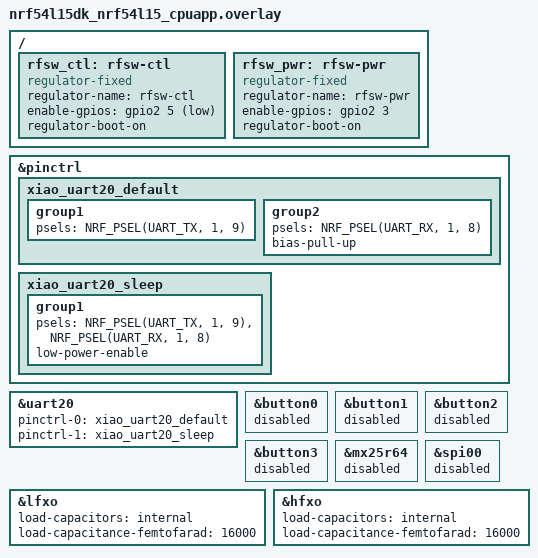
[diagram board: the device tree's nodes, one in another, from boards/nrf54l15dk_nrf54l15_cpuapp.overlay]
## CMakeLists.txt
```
# SPDX-License-Identifier: Apache-2.0
#
# Dedicated nRF54L15 LE Audio source fixture (RH1B): BAP
# unicast client that boots with persistent identity/bonds, accepts strict RH1A
# JSON via one quiet serial shell command, and runs a bounded
# connect/stream/teardown lifecycle with deterministic HIL1 records.
#
# Compiles the exact RH1A core modules (protocol, record, signal, state)
# plus the app coordinator, output queue/writer, TX send driver, and the
# real Bluetooth/BAP backend.  Production build has no test seam.

cmake_minimum_required(VERSION 3.20.0)
find_package(Zephyr REQUIRED HINTS $ENV{ZEPHYR_BASE})
project(hil_source_app)

if(NOT CONFIG_SOC_NRF54L15_CPUAPP)
  message(FATAL_ERROR "HIL source requires nRF54L15 CPUAPP")
endif()

target_sources(app PRIVATE
  src/main.c
  src/hil_source_app.c
  src/hil_source_controller_time_nrf54.c
  src/hil_source_output.c
  src/hil_source_tx.c
  src/hil_source_bap.c
  ${CMAKE_CURRENT_SOURCE_DIR}/../core/hil_source_protocol.c
  ${CMAKE_CURRENT_SOURCE_DIR}/../core/hil_source_record.c
  ${CMAKE_CURRENT_SOURCE_DIR}/../core/hil_source_signal.c
  ${CMAKE_CURRENT_SOURCE_DIR}/../core/hil_source_state.c
)

target_include_directories(app PRIVATE
  ${CMAKE_CURRENT_SOURCE_DIR}/src
  ${CMAKE_CURRENT_SOURCE_DIR}/../core
)

# LSP compile-database link: expose this app's compile_commands.json one
# directory up (hil/source/) so clangd's closest-ancestor discovery serves
# both this app tree and the ../core RH1A modules compiled into it.
# Idempotent; re-created on every reconfigure.
file(CREATE_LINK
     "${CMAKE_BINARY_DIR}/compile_commands.json"
     "${CMAKE_CURRENT_SOURCE_DIR}/../compile_commands.json"
     SYMBOLIC)
```

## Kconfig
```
# SPDX-License-Identifier: Apache-2.0
#
# Dedicated LE Audio source fixture application Kconfig.
#
# All run-time options are standard Zephyr/Bluetooth symbols set in
# prj.conf and the board conf. The RH1A core modules compile without any
# application-specific Kconfig; diagnostic fixture options live below.

source "Kconfig.zephyr"

config HIL_SOURCE_QOS_RTN
	int "HIL source CIS retransmission number (RTN)"
	default 5
	range 0 5
	help
	  RTN used in the source BAP QoS presets. Default 5 matches the
	  original frozen presets (nse=6). Diagnostic-only knob: the
	  receiver transport investigation varies it in fragments; normal
	  builds must not set it.

config HIL_SOURCE_QOS_PHY
	int "HIL source CIS PHY (1 or 2)"
	default 2
	range 1 2
	help
	  PHY used in the source BAP QoS presets. Default 2 (2M) matches the
	  original frozen presets. Diagnostic-only knob for the receiver
	  transport investigation; normal builds must not set it.

config HIL_SOURCE_TX_OUTSTANDING_TARGET
	int "HIL source TX outstanding target per stream"
	default 3
	range 1 6
	help
	  Per-stream in-flight SDU cap for the completion-paced TX loop.
	  Default 3 matches the original source-fixture backpressure design.
	  Diagnostic-only knob for the receiver transport investigation;
	  normal builds must not set it.
```

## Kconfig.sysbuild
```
# SPDX-License-Identifier: Apache-2.0
#
# Standalone nRF54L15 source builds with --no-sysbuild.

source "share/sysbuild/Kconfig"
```

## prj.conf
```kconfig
CONFIG_BT=y
CONFIG_BT_CENTRAL=y
CONFIG_BT_ISO_CENTRAL=y
CONFIG_BT_GATT_CLIENT=y
CONFIG_BT_GATT_AUTO_DISCOVER_CCC=y
CONFIG_BT_GATT_AUTO_UPDATE_MTU=y
CONFIG_BT_AUDIO=y
CONFIG_BT_BAP_UNICAST_CLIENT=y
CONFIG_BT_BAP_UNICAST_CLIENT_ASE_SNK_COUNT=2
CONFIG_BT_BAP_UNICAST_CLIENT_ASE_SRC_COUNT=0
CONFIG_BT_BAP_UNICAST_CLIENT_GROUP_STREAM_COUNT=2
CONFIG_BT_ISO_MAX_CHAN=2
CONFIG_BT_ISO_TX_MTU=255
CONFIG_BT_ISO_TX_BUF_COUNT=6
CONFIG_BT_SMP=y
CONFIG_BT_SMP_APP_PAIRING_ACCEPT=y
CONFIG_BT_SMP_ENFORCE_MITM=n
CONFIG_BT_KEYS_OVERWRITE_OLDEST=y
CONFIG_BT_SETTINGS=y
CONFIG_BT_PRIVACY=y
CONFIG_SETTINGS=y
CONFIG_FLASH=y
CONFIG_FLASH_MAP=y
CONFIG_FLASH_PAGE_LAYOUT=y
CONFIG_ZMS=y
CONFIG_SETTINGS_ZMS=y
CONFIG_BT_EXT_ADV=y
CONFIG_FPU=y
CONFIG_LIBLC3=y
CONFIG_SPEED_OPTIMIZATIONS=y
CONFIG_ASSERT=y
CONFIG_UTF8=y
CONFIG_NCS_BOOT_BANNER=n
CONFIG_BOOT_BANNER=n
CONFIG_SHELL=y
CONFIG_SHELL_BACKEND_SERIAL=y
# Keep HIL control shell above source worker/output threads during TX.
CONFIG_SHELL_THREAD_PRIORITY_OVERRIDE=y
CONFIG_SHELL_THREAD_PRIORITY=0
CONFIG_SHELL_CMD_BUFF_SIZE=512
CONFIG_SHELL_ARGC_MAX=3
CONFIG_SHELL_ECHO_STATUS=n
CONFIG_SHELL_VT100_COMMANDS=n
CONFIG_SHELL_METAKEYS=n
CONFIG_SHELL_TAB=n
CONFIG_SHELL_HISTORY=n
CONFIG_SHELL_WILDCARD=n
CONFIG_SHELL_MSG_CMD_NOT_FOUND=n
CONFIG_SHELL_HELP_ON_WRONG_ARGUMENT_COUNT=n
CONFIG_SHELL_PROMPT_CHANGE=n
CONFIG_SHELL_PROMPT_UART=""
CONFIG_SHELL_BACKEND_SERIAL_LOG_LEVEL_NONE=y
CONFIG_SHELL_TX_TIMEOUT_MS=0
CONFIG_SHELL_PRINTF_BUFF_SIZE=1024
CONFIG_SHELL_STACK_SIZE=8192
CONFIG_LOG=n
CONFIG_MAIN_STACK_SIZE=2048
CONFIG_SYSTEM_WORKQUEUE_STACK_SIZE=4096
CONFIG_BT_RX_STACK_SIZE=4096
CONFIG_HEAP_MEM_POOL_SIZE=4096
```

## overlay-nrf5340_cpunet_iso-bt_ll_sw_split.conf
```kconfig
# SPDX-License-Identifier: Apache-2.0
#
# Repository net-core overlay for the dedicated LE Audio source fixture.
# Applied on top of the hci_ipc sample base configuration
# (nrf5340_cpunet_iso_central-bt_ll_sw_split.conf) and may only tighten
# values: the fixture connects to exactly one receiver over two ISO
# streams with six controller TX buffers.

CONFIG_BT_MAX_CONN=1
CONFIG_BT_ISO_MAX_CHAN=2
CONFIG_BT_ISO_TX_BUF_COUNT=6
CONFIG_BT_CTLR_CONN_ISO_GROUPS=1
CONFIG_BT_CTLR_CONN_ISO_STREAMS=2
CONFIG_BT_CTLR_CONN_ISO_STREAMS_PER_GROUP=2
CONFIG_BT_CTLR_ISOAL_SOURCES=2
CONFIG_BT_CTLR_ISO_TX_BUFFERS=6
CONFIG_BT_CTLR_ISO_TX_BUFFER_SIZE=255
CONFIG_BT_CTLR_ISO_TX_SDU_LEN_MAX=247

# Dedicated lab source fixture. Use nRF5340's supported +3 dBm controller
# default so row commissioning does not depend on marginal 0 dBm RF links.
CONFIG_BT_CTLR_TX_PWR_PLUS_3=y

CONFIG_NCS_BOOT_BANNER=n
CONFIG_BOOT_BANNER=n
CONFIG_CONSOLE=n
CONFIG_UART_CONSOLE=n
CONFIG_STDOUT_CONSOLE=n
CONFIG_PRINTK=n
CONFIG_EARLY_CONSOLE=n
```

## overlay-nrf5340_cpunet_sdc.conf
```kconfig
# SPDX-License-Identifier: Apache-2.0
#
# Repository net-core overlay for the dedicated LE Audio source fixture:
# SoftDevice Controller (SDC) variant. Applied on top of the hci_ipc
# sample base prj.conf (controller-agnostic) instead of any SW-split
# sample configuration. The DT default on nrf5340_cpunet selects the
# SDC node (bt_hci_sdc okay, zephyr,bt-hci chosen), so no snippet and
# no DT overlay is needed; only this Kconfig overlay is applied.
#
# Decision record:
# docs/development/system-hil-rh3-modea10-sdc-handoff.md. The SW-split
# ISO-AL expires (SN_STRICT=y) or time-shifts (SN_STRICT=n) late TX SDUs
# under the completion-paced host at high CIG event duty; ModeA9 proved
# the mechanism and left the row failing frozen limits. SDC is the
# production-grade central ISO controller (BAP-tested per nrfxlib SDC
# isochronous_channels.rst; same shape as nrf5340_audio's SDC netcore +
# BAP unicast client host). Fixture connects to exactly one receiver
# over up to two connected ISO streams, central role only.

CONFIG_BT_BROADCASTER=n
CONFIG_BT_OBSERVER=y
CONFIG_BT_EXT_ADV=y
CONFIG_BT_PER_ADV=n
CONFIG_BT_PER_ADV_SYNC=n
CONFIG_BT_ISO_BROADCASTER=n
CONFIG_BT_ISO_SYNC_RECEIVER=n
CONFIG_BT_CENTRAL=y
CONFIG_BT_PERIPHERAL=n
CONFIG_BT_ISO_CENTRAL=y
CONFIG_BT_ISO_PERIPHERAL=n

# Host-side ISO channels for the raw-HCI IPC link. Keep the host ISO TX
# buffer count equal to the controller HCI TX buffer count (six) per the
# upstream sample's Newton's-cradle note.
CONFIG_BT_MAX_CONN=1
CONFIG_BT_ISO_MAX_CHAN=2
CONFIG_BT_ISO_TX_BUF_COUNT=6
CONFIG_BT_ISO_RX_BUF_COUNT=1

# Controller: SDC (default y on nrf5340 cpunet; DT default node),
# central ISO roles and buffers. One CIG, up to two CIS streams. The
# fixture is the audio source, so its ISO traffic is TX towards the
# receiver sink. Data-length and scan-data-length are SW-split-only
# symbols (BT_LL_SW_SPLIT dependency) and stay unset; SDC manages its
# own data length.
CONFIG_BT_LL_SOFTDEVICE=y
CONFIG_BT_CTLR_ASSERT_HANDLER=y

# Connected ISO: central role only. BT_CTLR_CONN_ISO is derived
# (default CENTRAL_ISO || PERIPHERAL_ISO) and not user-assignable;
# the central assignment below drives it. One CIG, up to two CIS
# streams.
CONFIG_BT_CTLR_CENTRAL_ISO=y
CONFIG_BT_CTLR_PERIPHERAL_ISO=n
CONFIG_BT_CTLR_CONN_ISO_GROUPS=1
CONFIG_BT_CTLR_CONN_ISO_STREAMS=2
CONFIG_BT_CTLR_CONN_ISO_STREAMS_PER_GROUP=2

# SDC ISO TX buffer pools. The HCI buffer count is shared across
# streams; its help text recommends larger values for short SDU
# intervals or quick successive sends. Six covers the completion-paced
# host bursts (outstanding target 3 per stream, two streams) and
# matches the app-core CONFIG_BT_ISO_TX_BUF_COUNT=6, keeping the three
# depths equal per the repo buffer-matching policy. PDU buffers per
# stream cover subevent pre-transmission and retransmission margin
# (SDC default 3 raised to the previous SW-split pool depth intent).
CONFIG_BT_CTLR_SDC_ISO_TX_HCI_BUFFER_COUNT=6
CONFIG_BT_CTLR_SDC_ISO_TX_PDU_BUFFER_PER_STREAM_COUNT=6

# SDC role counts: central-only fixture (zero peripheral roles).
CONFIG_BT_CTLR_SDC_PERIPHERAL_COUNT=0

# Clear application-core RTC0 when MPSL starts the controller RTC. The source
# scheduler uses this mirrored clock instead of deriving controller-now from an
# already-scheduled SDU timestamp.
CONFIG_MPSL_TRIGGER_IPC_TASK_ON_RTC_START=y
CONFIG_MPSL_TRIGGER_IPC_TASK_ON_RTC_START_CHANNEL=4

# TX power: +3 dBm, the nRF5340 maximum, keeps the fixture RF margin the
# SW-split build had (CONFIG_BT_CTLR_TX_PWR_PLUS_3). Under SDC the
# Zephyr TX_PWR choice is still consumed (nrf radio_nrf5_txp.h maps it
# to sdc_default_tx_power_set()), but its default is 0 dBm, so the
# assignment is required.
CONFIG_BT_CTLR_TX_PWR_PLUS_3=y

# Net core is silent; the app core owns the HIL1 console.
CONFIG_NCS_BOOT_BANNER=n
CONFIG_BOOT_BANNER=n
CONFIG_CONSOLE=n
CONFIG_UART_CONSOLE=n
CONFIG_STDOUT_CONSOLE=n
CONFIG_PRINTK=n
CONFIG_EARLY_CONSOLE=n
```

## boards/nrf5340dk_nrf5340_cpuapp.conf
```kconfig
# SPDX-License-Identifier: Apache-2.0
#
# nRF5340DK cpuapp board conf for the dedicated LE Audio source fixture.
# Mirrors the upstream bap_unicast_client nrf5340dk board conf: the HCI
# buffer sizes must cover the 255-byte ISO MTU and the extended events the
# host exchanges with the net-core controller (SDC via hci_ipc).

CONFIG_BT_BUF_EVT_RX_SIZE=255
CONFIG_BT_BUF_ACL_RX_SIZE=255
CONFIG_BT_BUF_ACL_TX_SIZE=251
CONFIG_BT_BUF_CMD_TX_SIZE=255

# Mirror the network-core controller RTC on application-core RTC0. Zephyr's
# system timer uses RTC1, leaving RTC0 for this synchronization route.
CONFIG_NRFX_RTC=y
CONFIG_NRFX_GPPI=y
```

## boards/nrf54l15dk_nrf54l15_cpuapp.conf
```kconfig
# SPDX-License-Identifier: Apache-2.0

# NCS 3.4.1: unused deprecated platform alias; SOC_SERIES_NRF54L remains enabled.
CONFIG_NRF_PLATFORM_LUMOS=n

CONFIG_REGULATOR=y
CONFIG_REGULATOR_FIXED_INIT_PRIORITY=45

CONFIG_BT_BUF_EVT_RX_SIZE=255
CONFIG_BT_BUF_ACL_RX_SIZE=255
CONFIG_BT_BUF_ACL_TX_SIZE=251
CONFIG_BT_BUF_CMD_TX_SIZE=255

# Bonded reconnect overflowed the 900-byte TX processor stack on the physical source.
# Budget this dedicated host/integrated-controller TX thread independently of RX.
CONFIG_BT_TX_PROCESSOR_STACK_SIZE=2048

CONFIG_BT_LL_SOFTDEVICE=y
CONFIG_BT_MAX_CONN=1
CONFIG_BT_CTLR_CENTRAL_ISO=y
CONFIG_BT_CTLR_PERIPHERAL_ISO=n
CONFIG_BT_CTLR_CONN_ISO_GROUPS=1
CONFIG_BT_CTLR_CONN_ISO_STREAMS=2
CONFIG_BT_CTLR_CONN_ISO_STREAMS_PER_GROUP=2
CONFIG_BT_CTLR_SDC_PERIPHERAL_COUNT=0
CONFIG_BT_CTLR_SDC_ISO_TX_HCI_BUFFER_COUNT=6
CONFIG_BT_CTLR_SDC_ISO_TX_PDU_BUFFER_PER_STREAM_COUNT=6
CONFIG_BT_CTLR_TX_PWR_PLUS_3=y
```

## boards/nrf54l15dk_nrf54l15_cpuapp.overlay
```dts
/*
 * Copyright (c) 2026
 * SPDX-License-Identifier: Apache-2.0
 *
 * XIAO nRF54L15 source-fixture overrides for the stock nrf54l15dk target.
 */

/ {
	rfsw_ctl: rfsw-ctl {
		compatible = "regulator-fixed";
		regulator-name = "rfsw-ctl";
		enable-gpios = <&gpio2 5 GPIO_ACTIVE_LOW>;
		regulator-boot-on;
	};

	rfsw_pwr: rfsw-pwr {
		compatible = "regulator-fixed";
		regulator-name = "rfsw-pwr";
		enable-gpios = <&gpio2 3 GPIO_ACTIVE_HIGH>;
		regulator-boot-on;
	};
};

&pinctrl {
	xiao_uart20_default: xiao_uart20_default {
		group1 {
			psels = <NRF_PSEL(UART_TX, 1, 9)>;
		};

		group2 {
			psels = <NRF_PSEL(UART_RX, 1, 8)>;
			bias-pull-up;
		};
	};

	xiao_uart20_sleep: xiao_uart20_sleep {
		group1 {
			psels = <NRF_PSEL(UART_TX, 1, 9)>,
				<NRF_PSEL(UART_RX, 1, 8)>;
			low-power-enable;
		};
	};
};

&uart20 {
	pinctrl-0 = <&xiao_uart20_default>;
	pinctrl-1 = <&xiao_uart20_sleep>;
	pinctrl-names = "default", "sleep";
};

&button0 {
	status = "disabled";
};

&button1 {
	status = "disabled";
};

&button2 {
	status = "disabled";
};

&button3 {
	status = "disabled";
};

&mx25r64 {
	status = "disabled";
};

&spi00 {
	status = "disabled";
};

&lfxo {
	load-capacitors = "internal";
	load-capacitance-femtofarad = <16000>;
	status = "okay";
};

&hfxo {
	load-capacitors = "internal";
	load-capacitance-femtofarad = <16000>;
	status = "okay";
};
```

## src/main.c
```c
/*
 * Copyright (c) 2026
 * SPDX-License-Identifier: Apache-2.0
 *
 * Dedicated LE Audio source fixture entry point.
 *
 * Initializes output and the nRF54L15 controller clock, then the Bluetooth/BAP
 * backend (bt_enable, settings_load, bt_is_ready, callbacks), then the app
 * coordinator (state and shell command), and returns into Zephyr threads.
 * A fatal init error emits one best-effort HIL1 status when possible and returns
 * nonzero; there is no restart loop.
 */

#include "hil_source_app.h"
#include "hil_source_bap.h"
#include "hil_source_controller_time.h"
#include "hil_source_output.h"

int main(void)
{
	int err;

	err = hil_source_output_init();
	if (err != 0) {
		/* No output available; nothing can be emitted. */
		return err;
	}

	err = hil_source_controller_time_init();
	if (err != 0) {
		hil_source_app_fatal_status("controller_time_init", err);
		return err;
	}

	err = hil_source_bap_init();
	if (err != 0) {
		hil_source_app_fatal_status("bap_init", err);
		return err;
	}

	err = hil_source_app_init();
	if (err != 0) {
		hil_source_app_fatal_status("app_init", err);
		return err;
	}

	return 0;
}
```

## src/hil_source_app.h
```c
/*
 * Copyright (c) 2026
 * SPDX-License-Identifier: Apache-2.0
 *
 * Dedicated LE Audio source fixture coordinator.
 *
 * The coordinator owns dispatch, the run worker, the TX stage
 * orchestration (pacing, lockstep, stage caps, outstanding, progress
 * timeout), the universal cleanup, and all HIL1 status/hello formatting.
 * All Bluetooth work happens through the backend ops table: in the
 * production build the table points at the real BAP/TX modules; under
 * CONFIG_HIL_SOURCE_APP_TEST the table is injected by the native test
 * suite so the coordinator runs against a scripted fake backend.
 */

#ifndef HIL_SOURCE_APP_H
#define HIL_SOURCE_APP_H

#include <stdbool.h>
#include <stddef.h>
#include <stdint.h>

#include <zephyr/bluetooth/addr.h>
#include <zephyr/kernel.h>

#include "hil_source_types.h"

#ifdef __cplusplus
extern "C" {
#endif

/* ── frozen timing / depth constants ──────────────────────────────── */

#define HIL_SOURCE_OP_TIMEOUT_CONNECT_MS    20000U
#define HIL_SOURCE_OP_TIMEOUT_SECURITY_MS   20000U
#define HIL_SOURCE_OP_TIMEOUT_DISCOVER_MS   10000U
#define HIL_SOURCE_OP_TIMEOUT_STREAM_MS     10000U
#define HIL_SOURCE_OUTPUT_SUBMIT_TIMEOUT_MS 1000U
#define HIL_SOURCE_IDLE_TERMINAL_WAIT_MS    15000U
#ifndef CONFIG_HIL_SOURCE_TX_OUTSTANDING_TARGET
#define HIL_SOURCE_TX_OUTSTANDING_TARGET 3U
#else
#define HIL_SOURCE_TX_OUTSTANDING_TARGET ((uint32_t)CONFIG_HIL_SOURCE_TX_OUTSTANDING_TARGET)
#endif
#define HIL_SOURCE_TX_PROGRESS_TIMEOUT_MS 2000U
#define HIL_SOURCE_TX_DRAIN_TIMEOUT_MS    5000U
#define HIL_SOURCE_MAX_STREAMS            2U

/* ── SDC timestamp-mode timing ─────────────────────────────────────── */

/* Encode first, then submit each pinned SDU against the direct nRF54L15
 * GRTC controller clock. The frozen 3000/2000 us margins retain headroom:
 * historically derived from SDC processing, the nRF53 reference scheduler's
 * IPC allowance, and worker/HCI jitter. Current XIAO uses no cross-core IPC. */
#define HIL_SOURCE_TX_TS_LEAD_TARGET_US 3000U
/* Pins closer than this to controller-now advance by whole intervals and
 * count as "pin_adv" evidence. */
#define HIL_SOURCE_TX_TS_MIN_AHEAD_US   2000U

/* Maximum encoded TX SDU byte size.  The ISO TX path is bounded by
 * CONFIG_BT_ISO_TX_MTU (255); the coordinator never uses the 1024-byte
 * output line scratch as SDU scratch. */
#define HIL_SOURCE_TX_SDU_MAX 255U

enum hil_source_stream_connect_outcome {
	HIL_SOURCE_STREAM_CONNECT_OUTCOME_CONNECTED,
	HIL_SOURCE_STREAM_CONNECT_OUTCOME_RETRYABLE_FAILURE,
	HIL_SOURCE_STREAM_CONNECT_OUTCOME_ERROR,
};

/* ── backend ops ──────────────────────────────────────────────────── */

struct hil_source_backend_ops {
	/* identity / bonds */
	int (*get_identity)(bt_addr_le_t *out);
	int (*bond_count)(void);
	int (*unpair)(const bt_addr_le_t *peer);
	/* True when the exact configured peer (address + type) has a stored
	 * bond.  Used to require an L2 bond before discovery on both fresh
	 * pairing and bonded reconnect. */
	bool (*peer_bonded)(const bt_addr_le_t *peer);

	/* run shape applied once per segment before connect */
	void (*set_run_shape)(enum hil_source_mode mode, enum hil_source_profile profile);

	/* run lifecycle: kick + completion sem */
	int (*kick_connect)(const bt_addr_le_t *addr);
	int (*kick_security)(void);
	int (*kick_discover)(void);
	int (*kick_configure)(uint8_t stream_count);
	int (*kick_qos)(uint8_t stream_count);
	/* Submit exactly one enable request for stream_idx.  The coordinator
	 * serializes multi-stream enable by waiting for sem_enabled and checking
	 * op_error before submitting the next stream. */
	int (*kick_enable)(uint8_t stream_idx);
	/* Submit one CIS connection request for stream_idx.  NCS permits only
	 * one pending bt_bap_stream_connect(); the coordinator waits for the
	 * matching public stream_ops.connected() completion before submitting the
	 * next request, and matching failed-CIS stream_ops.disconnected()
	 * completion is treated as a retryable failure, with at most one
	 * coordinator-worker retry for that same stream. */
	int (*kick_stream_connect)(uint8_t stream_idx);
	int (*kick_start)(uint8_t stream_count);

	/* Explicit TX activation: called once per segment after every
	 * sem_started completion and before the run advances to streaming.
	 * Production attaches the current segment's stream objects to the
	 * TX driver; the fake records the call. */
	int (*tx_start)(uint8_t stream_count);

	struct k_sem *(*sem_connected)(void);
	struct k_sem *(*sem_security)(void);
	struct k_sem *(*sem_discovered)(void);
	struct k_sem *(*sem_configured)(void);
	struct k_sem *(*sem_qos)(void);
	struct k_sem *(*sem_enabled)(void);
	struct k_sem *(*sem_stream_connected)(void);
	enum hil_source_stream_connect_outcome (*stream_connect_outcome)(uint8_t stream_idx);
	struct k_sem *(*sem_started)(void);

	/* most recent async lifecycle operation error (0 = none); the
	 * coordinator checks it after every bounded wait */
	int (*op_error)(void);

	/* TX send driver */
	int (*tx_send)(uint8_t stream_idx, uint16_t seq, const uint8_t *sdu, size_t len);
	/* Timestamp-pinned send (SDC timestamps mode): provide the SDU for the ISO
	 * event starting at `ts` (controller clock, us). A successful call does not
	 * prove peer receipt. A single untimestamped bootstrap SDU on stream 0
	 * establishes the CIG base; all regular segment SDUs use this API.
	 * Production backend must not wait for allocation, credits, or completion:
	 * coordinator holds app ownership and scheduling across a peer batch. */
	int (*tx_send_ts)(uint8_t stream_idx, uint16_t seq, const uint8_t *sdu, size_t len,
			  uint32_t ts);
	/* Read the controller-assigned event timestamp (us) for the previously
	 * provided SDU on a stream. Thread context only (synchronous HCI in
	 * production; scripted in the fake). */
	int (*tx_read_tx_ts)(uint8_t stream_idx, uint32_t *ts);
	/* Read controller time modulo 2^32 us. This must share the SDC clock
	 * domain; host uptime is not interchangeable with controller time.
	 * Must be a local nonblocking clock read, not a synchronous HCI command. */
	int (*tx_time_get)(uint32_t *time_us);
	/* Read HCI LE_Read_ISO_TX_Sync. Success requires a previously scheduled SDU,
	 * but repeated polls may return that same SDU. Historical "air" status
	 * counts therefore count successful polls, not aired SDUs. */
	int (*tx_read_sync)(uint8_t stream_idx, uint32_t *ts, uint32_t *seq);
	void (*tx_stop)(void);

	/* teardown */
	int (*kick_disable)(uint8_t stream_idx);
	struct k_sem *(*sem_disabled)(void);
	int (*kick_release)(uint8_t stream_idx);
	struct k_sem *(*sem_released)(void);
	int (*kick_disconnect)(void);
	struct k_sem *(*sem_disconnected)(void);
	bool (*conn_present)(void);
	bool (*stream_attached)(uint8_t stream_idx);
	int (*kick_group_delete)(void);
	void (*conn_unref)(void);
	void (*reset_segment)(void);

	/* status getters */
	uint8_t (*security_level)(void);
	int (*security_error)(void);
	uint8_t (*discovered_sink_count)(void);
	bool (*group_present)(void);
	uint8_t (*disconnect_reason)(void);
	uint8_t (*first_ascs_code)(void);
	uint8_t (*first_ascs_reason)(void);
};

/* ── public API ───────────────────────────────────────────────────── */

/* Initialize the coordinator: requires an active output (init order:
 * output first, then app), an injected/static backend, resets the run
 * state and configured IDs, and starts the worker thread.  Returns 0 or
 * a negative errno; a fatal init failure is not retried. */
int hil_source_app_init(void);

/* One best-effort HIL1 status record for a fatal boot failure
 * (kind status, command_id/run_id "boot", ok:false, error failed, with
 * the failing phase and errno in trusted data).  Never blocks the boot
 * path; a submit failure is swallowed. */
void hil_source_app_fatal_status(const char *phase, int err);

/* Dispatch one `hil <raw JSON>` command body (exactly the JSON object
 * span after the command name).  Returns 0 when the command was accepted
 * for handling or a negative errno for a rejected request. */
int hil_source_app_dispatch(const char *json, size_t len);

/* Sent-callback entry point, called by the real BAP stream ops in production
 * and by the fake backend in native tests. Decrements current-generation
 * outstanding and records callbacks while a run remains active. Callbacks
 * after teardown do not change logical outstanding. */
void hil_source_app_tx_sent(uint8_t stream_idx);

/* Format the full current status HIL1 line (envelope included) into buf.
 * Returns the written length or a negative errno; on failure the buffer
 * is an empty C string when cap is nonzero.  Exposed so tests can prove
 * formatter truncation fails closed. */
int hil_source_app_format_status_line(char *buf, size_t cap, const char *command_id,
				      const char *run_id);

#ifdef CONFIG_HIL_SOURCE_APP_TEST
/* Test seam: inject the backend ops table.  Must be called before
 * hil_source_app_init(). */
void hil_source_app_test_set_backend(const struct hil_source_backend_ops *ops);
#endif /* CONFIG_HIL_SOURCE_APP_TEST */

#ifdef __cplusplus
}
#endif

#endif /* HIL_SOURCE_APP_H */
```

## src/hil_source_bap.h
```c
/*
 * Copyright (c) 2026
 * SPDX-License-Identifier: Apache-2.0
 *
 * Real Bluetooth/BAP backend for the dedicated LE Audio source fixture
 * (RH1B).  Owns the connection, the BAP unicast client callbacks, the two
 * sink streams/endpoints, the unicast group, and the teardown primitives;
 * exposes them to the coordinator through the production backend ops
 * table.  Never drives lifecycle itself: the coordinator worker owns all
 * blocking operations.
 */

#ifndef HIL_SOURCE_BAP_H
#define HIL_SOURCE_BAP_H

#include "hil_source_app.h"

#ifdef __cplusplus
extern "C" {
#endif

/* Boot the Bluetooth/BAP backend: bt_enable(NULL), settings_load(),
 * require bt_is_ready(), register connection auth/auth-info callbacks,
 * GATT and BAP unicast client callbacks, register the stream ops, and
 * initialize the TX driver.  Returns 0 or a negative errno. */
int hil_source_bap_init(void);

/* The production backend ops table bound to the real BAP/TX modules. */
const struct hil_source_backend_ops *hil_source_bap_ops(void);

#ifdef __cplusplus
}
#endif

#endif /* HIL_SOURCE_BAP_H */
```

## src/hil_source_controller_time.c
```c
/*
 * Copyright (c) 2026
 * SPDX-License-Identifier: Apache-2.0
 *
 * Mirror the nRF5340 network-core controller RTC on application-core RTC0.
 * MPSL publishes its RTC-start event over IPC channel 4; PPI clears RTC0 on
 * that event. Only current controller time is needed here, so no high-frequency
 * TIMER or hardware presentation trigger is configured.
 */

#include <errno.h>
#include <stdbool.h>
#include <stdint.h>

#include <hal/nrf_ipc.h>
#include <helpers/nrfx_gppi.h>
#include <nrfx_rtc.h>
#include <zephyr/device.h>
#include <zephyr/drivers/mbox.h>
#include <zephyr/init.h>
#include <zephyr/irq.h>
#include <zephyr/kernel.h>

#include "hil_source_controller_time.h"

#define HIL_SOURCE_CONTROLLER_IPC_CHANNEL      4U
#define HIL_SOURCE_CONTROLLER_RTC_COUNTER_BITS 24U

static nrfx_rtc_t controller_rtc = NRFX_RTC_INSTANCE(NRF_RTC0);
static nrfx_gppi_handle_t rtc_start_connection;
static volatile uint32_t rtc_overflows;
static volatile bool controller_time_synchronized;
static volatile bool controller_time_fault;
static volatile bool controller_start_seen;
static bool controller_time_initialized;

static void controller_start_handler(const struct device *dev, mbox_channel_id_t channel_id,
				     void *user_data, struct mbox_msg *data)
{
	ARG_UNUSED(dev);
	ARG_UNUSED(channel_id);
	ARG_UNUSED(user_data);
	ARG_UNUSED(data);

	/* One APP boot supports one controller clock epoch. A second pulse means
	 * CPUNET restarted while APP remained alive. PPI already cleared RTC0, so
	 * fail closed instead of combining epochs. */
	if (controller_start_seen) {
		controller_time_synchronized = false;
		controller_time_fault = true;
		return;
	}
	nrf_rtc_event_clear(controller_rtc.p_reg, NRF_RTC_EVENT_OVERFLOW);
	rtc_overflows = 0U;
	controller_start_seen = true;
	controller_time_synchronized = true;
}

static void controller_rtc_handler(nrf_rtc_event_t event_type, void *context)
{
	ARG_UNUSED(context);

	if (event_type == NRF_RTC_EVENT_OVERFLOW && controller_time_synchronized &&
	    !controller_time_fault) {
		rtc_overflows++;
	}
}

int hil_source_controller_time_init(void)
{
	const nrfx_rtc_config_t config = NRFX_RTC_DEFAULT_CONFIG;
	const struct device *mbox = DEVICE_DT_GET(DT_NODELABEL(mbox));
	uint32_t event_endpoint;
	uint32_t task_endpoint;
	int ret;

	if (controller_time_initialized) {
		return 0;
	}
	if (!device_is_ready(mbox)) {
		return -ENODEV;
	}
	controller_time_synchronized = false;
	controller_time_fault = false;
	controller_start_seen = false;
	rtc_overflows = 0U;

	ret = nrfx_rtc_init(&controller_rtc, &config, controller_rtc_handler);
	if (ret != 0) {
		return ret;
	}

	IRQ_CONNECT(NRFX_IRQ_NUMBER_GET(NRF_RTC_INST_GET(0)), IRQ_PRIO_LOWEST, nrfx_rtc_irq_handler,
		    &controller_rtc, 0);
	nrfx_rtc_overflow_enable(&controller_rtc, true);
	nrfx_rtc_counter_clear(&controller_rtc);

	ret = mbox_register_callback(mbox, HIL_SOURCE_CONTROLLER_IPC_CHANNEL,
				     controller_start_handler, NULL);
	if (ret != 0) {
		goto fail_rtc;
	}

	/* Mbox driver maps receive event 4 to channel 4. Arm its event-to-RTC0
	 * route before Bluetooth can start CPUNET. */
	nrf_ipc_event_clear(NRF_IPC, NRF_IPC_EVENT_RECEIVE_4);
	event_endpoint = nrf_ipc_event_address_get(NRF_IPC, NRF_IPC_EVENT_RECEIVE_4);
	task_endpoint = nrfx_rtc_task_address_get(&controller_rtc, NRF_RTC_TASK_CLEAR);
	ret = nrfx_gppi_conn_alloc(event_endpoint, task_endpoint, &rtc_start_connection);
	if (ret < 0) {
		goto fail_callback;
	}
	nrfx_gppi_conn_enable(rtc_start_connection);

	ret = mbox_set_enabled(mbox, HIL_SOURCE_CONTROLLER_IPC_CHANNEL, true);
	if (ret != 0) {
		goto fail_connection;
	}
	nrfx_rtc_enable(&controller_rtc);

	controller_time_initialized = true;
	return 0;

fail_connection:
	nrfx_gppi_conn_disable(rtc_start_connection);
	nrfx_gppi_conn_free(event_endpoint, task_endpoint, rtc_start_connection);
fail_callback:
	(void)mbox_register_callback(mbox, HIL_SOURCE_CONTROLLER_IPC_CHANNEL, NULL, NULL);
fail_rtc:
	nrfx_rtc_uninit(&controller_rtc);
	return ret;
}

int hil_source_controller_time_get(uint32_t *time_us)
{
	uint64_t ticks;
	uint32_t overflows;
	uint32_t counter;
	unsigned int key;

	if (time_us == NULL) {
		return -EINVAL;
	}
	/* Keep overflow accounting coherent if wrap occurs while IRQ delivery is
	 * masked. One RTC tick is 1 / 32768 s; 15625 / 512 is the exact
	 * microsecond conversion ratio. */
	key = irq_lock();
	if (controller_time_fault) {
		irq_unlock(key);
		return -EIO;
	}
	if (!controller_time_synchronized ||
	    nrf_ipc_event_check(NRF_IPC, NRF_IPC_EVENT_RECEIVE_4)) {
		irq_unlock(key);
		return -EAGAIN;
	}
	overflows = rtc_overflows;
	counter = nrf_rtc_counter_get(controller_rtc.p_reg);
	if (nrf_rtc_event_check(controller_rtc.p_reg, NRF_RTC_EVENT_OVERFLOW)) {
		counter = nrf_rtc_counter_get(controller_rtc.p_reg);
		overflows++;
	}
	if (nrf_ipc_event_check(NRF_IPC, NRF_IPC_EVENT_RECEIVE_4)) {
		irq_unlock(key);
		return -EAGAIN;
	}
	irq_unlock(key);

	ticks = ((uint64_t)overflows << HIL_SOURCE_CONTROLLER_RTC_COUNTER_BITS) + counter;
	*time_us = (uint32_t)((ticks * 15625ULL) / 512ULL);
	return 0;
}

static int hil_source_controller_time_sys_init(void)
{
	return hil_source_controller_time_init();
}

/* Arm as early as Nordic's reference implementation. main() calls the same
 * idempotent initializer and checks its result, so init failure is observable. */
SYS_INIT(hil_source_controller_time_sys_init, POST_KERNEL, CONFIG_KERNEL_INIT_PRIORITY_DEFAULT);
```

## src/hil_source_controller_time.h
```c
/*
 * Copyright (c) 2026
 * SPDX-License-Identifier: Apache-2.0
 *
 * Platform view of the SoftDevice Controller clock.
 */

#ifndef HIL_SOURCE_CONTROLLER_TIME_H
#define HIL_SOURCE_CONTROLLER_TIME_H

#include <stdint.h>

#ifdef __cplusplus
extern "C" {
#endif

/* Initialize platform controller-clock infrastructure. */
int hil_source_controller_time_init(void);

/* Read nRF54L15 controller time from Zephyr-owned GRTC, modulo 2^32 us.
 * NULL returns -EINVAL; uninitialized GRTC returns -ENODEV; not-ready
 * GRTC returns -EAGAIN. On success, writes *time_us and returns 0.
 * No network-core mirror or mirrored clock epoch is used. */
int hil_source_controller_time_get(uint32_t *time_us);

#ifdef __cplusplus
}
#endif

#endif /* HIL_SOURCE_CONTROLLER_TIME_H */
```

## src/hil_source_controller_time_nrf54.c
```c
/*
 * Copyright (c) 2026
 * SPDX-License-Identifier: Apache-2.0
 *
 * Read the nRF54L15 SoftDevice Controller clock from Zephyr-owned GRTC.
 */

#include <errno.h>
#include <stdint.h>

#include <nrfx_grtc.h>

#include "hil_source_controller_time.h"

int hil_source_controller_time_init(void)
{
	return nrfx_grtc_init_check() ? 0 : -ENODEV;
}

int hil_source_controller_time_get(uint32_t *time_us)
{
	if (time_us == NULL) {
		return -EINVAL;
	}
	if (!nrfx_grtc_init_check()) {
		return -ENODEV;
	}
	if (!nrfx_grtc_ready_check()) {
		return -EAGAIN;
	}

	*time_us = (uint32_t)nrfx_grtc_syscounter_get();
	return 0;
}
```

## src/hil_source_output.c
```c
/*
 * Copyright (c) 2026
 * SPDX-License-Identifier: Apache-2.0
 *
 * HIL1 output queue and single writer (RH1B).
 *
 * One queue (eight lines of 1024 bytes plus length) and one writer thread.
 * Validation happens before enqueue: a rejected line is never truncated
 * and never partially emitted.  A queue timeout on submit is a fatal
 * runtime error the caller (coordinator) turns into an abort.  Under
 * CONFIG_HIL_SOURCE_APP_TEST the writer thread is replaced by a
 * test-owned drain so native tests capture exact submitted lines without
 * a shell.
 */

#include <errno.h>
#include <string.h>

#include <zephyr/kernel.h>
#include <zephyr/shell/shell.h>
#include <zephyr/shell/shell_uart.h>
#include <zephyr/sys/util.h>

#include "hil_source_output.h"

struct hil_source_output_line {
	char data[HIL_SOURCE_OUTPUT_LINE_SIZE];
	uint16_t len;
};

K_MSGQ_DEFINE(output_queue, sizeof(struct hil_source_output_line), HIL_SOURCE_OUTPUT_QUEUE_DEPTH,
	      4);
static bool output_active;

#if !defined(CONFIG_HIL_SOURCE_APP_TEST)
/* Each dequeue owns one 1026-byte output line on stack before shell_fprintf()
 * adds its call depth. Keep enough bounded headroom for both operations. */
K_THREAD_STACK_DEFINE(output_writer_stack, 4096);
static struct k_thread output_writer_thread;

static void output_writer_fn(void *a, void *b, void *c)
{
	const struct shell *sh = shell_backend_uart_get_ptr();
	struct hil_source_output_line line;

	ARG_UNUSED(a);
	ARG_UNUSED(b);
	ARG_UNUSED(c);

	while (true) {
		if (k_msgq_get(&output_queue, &line, K_FOREVER) != 0) {
			continue;
		}
		if (sh != NULL) {
			shell_fprintf(sh, SHELL_NORMAL, "%.*s\n", (int)line.len, line.data);
		}
	}
}
#endif /* !CONFIG_HIL_SOURCE_APP_TEST */

#ifdef CONFIG_HIL_SOURCE_APP_TEST
static void (*capture_fn)(const char *line, size_t len, void *arg);
static void *capture_arg;
#endif

int hil_source_output_init(void)
{
	if (output_active) {
		return 0; /* idempotent */
	}
#if !defined(CONFIG_HIL_SOURCE_APP_TEST)
	/* Production output requires a live serial shell backend before the
	 * writer may start; without it every line would be silently dropped.
	 * The test build stays capture-backed and never requires the shell. */
	if (shell_backend_uart_get_ptr() == NULL) {
		return -ENODEV;
	}
#endif /* !CONFIG_HIL_SOURCE_APP_TEST */
	k_msgq_purge(&output_queue);
	output_active = true;

#if !defined(CONFIG_HIL_SOURCE_APP_TEST)
	k_thread_create(&output_writer_thread, output_writer_stack,
			K_KERNEL_STACK_SIZEOF(output_writer_stack), output_writer_fn, NULL, NULL,
			NULL, K_PRIO_PREEMPT(6), 0, K_NO_WAIT);
	k_thread_name_set(&output_writer_thread, "hil_output");
#endif /* !CONFIG_HIL_SOURCE_APP_TEST */

	return 0;
}

bool hil_source_output_active(void)
{
	return output_active;
}

int hil_source_output_submit(const char *line, size_t len, uint32_t timeout_ms)
{
	struct hil_source_output_line entry;
	k_timeout_t timeout;
	size_t i;

	if (!output_active || line == NULL) {
		return -ENODEV;
	}
	if (len > HIL_SOURCE_OUTPUT_LINE_SIZE) {
		return -EOVERFLOW;
	}
	/* Only HIL1-prefixed records may leave the fixture; everything else
	 * is rejected up front. */
	if (len < 5U || memcmp(line, "HIL1 ", 5U) != 0) {
		return -EINVAL;
	}
	for (i = 0U; i < len; i++) {
		char c = line[i];

		if (c == '\r' || c == '\n' || c == '\0') {
			return -EINVAL;
		}
	}
	if (len == 0U) {
		return -EINVAL;
	}

	entry.len = (uint16_t)len;
	memcpy(entry.data, line, len);

	timeout = (timeout_ms == 0U) ? K_NO_WAIT : K_MSEC(timeout_ms);
	if (k_msgq_put(&output_queue, &entry, timeout) != 0) {
		return -EAGAIN;
	}
	return 0;
}

#ifdef CONFIG_HIL_SOURCE_APP_TEST
void hil_source_output_test_set_capture(void (*fn)(const char *line, size_t len, void *arg),
					void *arg)
{
	capture_fn = fn;
	capture_arg = arg;
}

uint32_t hil_source_output_test_drain(void)
{
	struct hil_source_output_line entry;
	uint32_t drained = 0U;

	while (k_msgq_get(&output_queue, &entry, K_NO_WAIT) == 0) {
		if (capture_fn != NULL) {
			capture_fn(entry.data, entry.len, capture_arg);
		}
		drained++;
	}
	return drained;
}
#endif /* CONFIG_HIL_SOURCE_APP_TEST */
```

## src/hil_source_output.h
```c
/*
 * Copyright (c) 2026
 * SPDX-License-Identifier: Apache-2.0
 *
 * HIL1 output queue and single writer (RH1B).
 *
 * Every HIL1 line, command response, and async event leaves the fixture
 * through this one module: one queue and one writer thread.  No direct
 * printk/printf/shell_print/shell_fprintf outside hil_source_output.c.
 */

#ifndef HIL_SOURCE_OUTPUT_H
#define HIL_SOURCE_OUTPUT_H

#include <stdbool.h>
#include <stddef.h>
#include <stdint.h>

#ifdef __cplusplus
extern "C" {
#endif

/* Queue holds eight complete lines of 1024 bytes plus length. 1024 bytes
 * fits the maximum legal command/run IDs (63/64) in a two-stream status
 * record; the TX SDU path is separately bounded by HIL_SOURCE_TX_SDU_MAX
 * and never uses this scratch. */
#define HIL_SOURCE_OUTPUT_LINE_SIZE   1024U
#define HIL_SOURCE_OUTPUT_QUEUE_DEPTH 8U

/* Initialize the output queue and start the writer thread (production
 * build).  Under CONFIG_HIL_SOURCE_APP_TEST no thread is started; the
 * test drains the queue through hil_source_output_test_drain().  Returns
 * 0 or a negative errno. */
int hil_source_output_init(void);

/* True once init succeeded and before any shutdown; inactive output
 * rejects submissions. */
bool hil_source_output_active(void);

/* Submit one complete line (no line terminator).  Rejects a non-HIL1
 * prefix, an embedded CR/LF/NUL, an overlong line, or an inactive output;
 * never truncates.  `timeout_ms` bounds the queue wait (the worker and
 * dispatch paths use 1000 ms; a queue timeout is a fatal runtime error
 * and triggers an abort where a run exists).  Returns 0 or a negative
 * errno. */
int hil_source_output_submit(const char *line, size_t len, uint32_t timeout_ms);

#ifdef CONFIG_HIL_SOURCE_APP_TEST
/* Test seam: set the capture callback invoked for every drained line.
 * Passing a NULL fn disables capture (lines are still drained). */
void hil_source_output_test_set_capture(void (*fn)(const char *line, size_t len, void *arg),
					void *arg);

/* Drain every queued line through the capture callback and return the
 * number of drained lines. */
uint32_t hil_source_output_test_drain(void);
#endif /* CONFIG_HIL_SOURCE_APP_TEST */

#ifdef __cplusplus
}
#endif

#endif /* HIL_SOURCE_OUTPUT_H */
```

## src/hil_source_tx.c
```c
/*
 * Copyright (c) 2026
 * SPDX-License-Identifier: Apache-2.0
 *
 * TX send driver: fixed net_buf pool + bt_bap_stream_send(), plus
 * SDC timestamp-mode support: bt_bap_stream_send_ts() and the HCI VS ISO
 * Read TX Timestamp readback used to establish the CIG event grid
 * (nrfxlib SDC isochronous_channels.rst "preferred way of providing data").
 */

#include <errno.h>
#include <string.h>

#include <zephyr/bluetooth/audio/bap.h>
#include <zephyr/bluetooth/hci.h>
#include <zephyr/bluetooth/iso.h>
#include <zephyr/kernel.h>
#include <zephyr/net_buf.h>

#include <bluetooth/hci_vs_sdc.h>

#include "hil_source_tx.h"

#define HIL_SOURCE_TX_POOL_COUNT          CONFIG_BT_ISO_TX_BUF_COUNT
#define HIL_SOURCE_TX_MTU                 CONFIG_BT_ISO_TX_MTU
#define HIL_SOURCE_TX_CONN_HANDLE_INVALID UINT16_MAX

static struct bt_bap_stream *tx_streams[HIL_SOURCE_MAX_TX_STREAMS];
static uint8_t tx_stream_count;
static bool tx_stopped;
/* Cached ISO connection handles per stream. HCI handle zero is valid, so
 * UINT16_MAX marks an unresolved handle. */
static uint16_t tx_conn_handles[HIL_SOURCE_MAX_TX_STREAMS];

NET_BUF_POOL_FIXED_DEFINE(tx_pool, HIL_SOURCE_TX_POOL_COUNT, BT_ISO_SDU_BUF_SIZE(HIL_SOURCE_TX_MTU),
			  CONFIG_BT_CONN_TX_USER_DATA_SIZE, NULL);

int hil_source_tx_init(void)
{
	tx_stopped = false;
	return 0;
}

int hil_source_tx_attach(struct bt_bap_stream *streams, uint8_t count)
{
	uint8_t i;

	if (streams == NULL || count == 0U || count > HIL_SOURCE_MAX_TX_STREAMS) {
		return -EINVAL;
	}
	for (i = 0U; i < count; i++) {
		tx_streams[i] = &streams[i];
		tx_conn_handles[i] = HIL_SOURCE_TX_CONN_HANDLE_INVALID;
	}
	tx_stream_count = count;
	tx_stopped = false;
	return 0;
}

int hil_source_tx_send(uint8_t stream_idx, uint16_t seq, const uint8_t *sdu, size_t len)
{
	struct bt_bap_stream *stream;
	struct net_buf *buf;
	int err;

	if (tx_stopped) {
		return -EIO;
	}
	if (stream_idx >= tx_stream_count || sdu == NULL || len == 0U) {
		return -EINVAL;
	}
	if (len > HIL_SOURCE_TX_MTU) {
		return -EOVERFLOW;
	}
	stream = tx_streams[stream_idx];

	buf = net_buf_alloc(&tx_pool, K_NO_WAIT);
	if (buf == NULL) {
		return -ENOBUFS;
	}
	net_buf_reserve(buf, BT_ISO_CHAN_SEND_RESERVE);
	net_buf_add_mem(buf, sdu, len);

	err = bt_bap_stream_send(stream, buf, seq);
	if (err != 0) {
		net_buf_unref(buf);
		return err;
	}
	return 0;
}

int hil_source_tx_send_ts(uint8_t stream_idx, uint16_t seq, const uint8_t *sdu, size_t len,
			  uint32_t ts)
{
	struct bt_bap_stream *stream;
	struct net_buf *buf;
	int err;

	if (tx_stopped) {
		return -EIO;
	}
	if (stream_idx >= tx_stream_count || sdu == NULL || len == 0U) {
		return -EINVAL;
	}
	if (len > HIL_SOURCE_TX_MTU) {
		return -EOVERFLOW;
	}
	stream = tx_streams[stream_idx];

	buf = net_buf_alloc(&tx_pool, K_NO_WAIT);
	if (buf == NULL) {
		return -ENOBUFS;
	}
	net_buf_reserve(buf, BT_ISO_CHAN_SEND_RESERVE);
	net_buf_add_mem(buf, sdu, len);

	err = bt_bap_stream_send_ts(stream, buf, seq, ts);
	if (err != 0) {
		net_buf_unref(buf);
		return err;
	}
	return 0;
}

int hil_source_tx_read_sync(uint8_t stream_idx, uint32_t *ts, uint32_t *seq)
{
	struct bt_bap_stream *stream;
	struct bt_iso_tx_info info;
	int err;

	if (ts == NULL || seq == NULL) {
		return -EINVAL;
	}
	if (tx_stopped || stream_idx >= tx_stream_count) {
		return -EIO;
	}
	stream = tx_streams[stream_idx];

	err = bt_bap_stream_get_tx_sync(stream, &info);
	if (err != 0) {
		return err;
	}
	*ts = info.ts;
	*seq = info.seq_num;
	return 0;
}

int hil_source_tx_read_tx_ts(uint8_t stream_idx, uint32_t *ts)
{
	struct bt_bap_stream *stream;
	sdc_hci_cmd_vs_iso_read_tx_timestamp_t params;
	sdc_hci_cmd_vs_iso_read_tx_timestamp_return_t rsp;
	uint16_t conn_handle;
	int err;

	if (ts == NULL) {
		return -EINVAL;
	}
	if (tx_stopped || stream_idx >= tx_stream_count) {
		return -EIO;
	}
	stream = tx_streams[stream_idx];

	conn_handle = tx_conn_handles[stream_idx];
	if (conn_handle == HIL_SOURCE_TX_CONN_HANDLE_INVALID) {
		const struct bt_conn *iso_conn;

		/* bt_bap_stream.iso is the public ISO channel reference,
		 * valid once the stream is in a group (bap.h). */
		if (stream->iso == NULL || stream->iso->iso == NULL) {
			return -ENOTCONN;
		}
		iso_conn = stream->iso->iso;
		err = bt_hci_get_conn_handle(iso_conn, &conn_handle);
		if (err != 0) {
			return err;
		}
		tx_conn_handles[stream_idx] = conn_handle;
	}

	params.conn_handle = conn_handle;
	err = hci_vs_sdc_iso_read_tx_timestamp(&params, &rsp);
	if (err != 0) {
		return err;
	}
	*ts = rsp.tx_time_stamp;
	return 0;
}

void hil_source_tx_stop(void)
{
	uint8_t i;

	tx_stopped = true;
	/* Reject further sends and clear the attached stream pointers and
	 * count: the next tx_start re-activates only the exact current
	 * segment stream count. */
	for (i = 0U; i < HIL_SOURCE_MAX_TX_STREAMS; i++) {
		tx_streams[i] = NULL;
		tx_conn_handles[i] = HIL_SOURCE_TX_CONN_HANDLE_INVALID;
	}
	tx_stream_count = 0U;
}
```

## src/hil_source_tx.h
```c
/*
 * Copyright (c) 2026
 * SPDX-License-Identifier: Apache-2.0
 *
 * TX send driver for the dedicated LE Audio source fixture.
 *
 * Production TX path: a fixed net_buf pool sized for the
 * 255-byte ISO MTU, reserve of BT_ISO_CHAN_SEND_RESERVE, and the actual
 * bt_bap_stream_send() calls. The coordinator owns frame pacing,
 * lockstep, stage caps, sequence/outstanding bookkeeping, and submitted
 * counters; this module only moves encoded SDUs onto a stream.
 *
 * SDC timestamp mode: hil_source_tx_send_ts() provides one SDU for a
 * controller-clock ISO event via bt_bap_stream_send_ts().
 * hil_source_tx_read_tx_ts() reads the event timestamp assigned to the
 * previously provided SDU through the SDC HCI VS command. Nordic SDK
 * iso_time_sync and nrf5340_audio are external reference patterns, not
 * required board targets. One untimestamped bootstrap SDU
 * on stream 0 establishes the shared CIG event grid. All regular segment SDUs
 * then use the learned grid.
 */

#ifndef HIL_SOURCE_TX_H
#define HIL_SOURCE_TX_H

#include <stddef.h>
#include <stdint.h>

#include <zephyr/bluetooth/audio/bap.h>

/* Maximum number of concurrent TX streams (two for Mode A). */
#define HIL_SOURCE_MAX_TX_STREAMS 2U

#ifdef __cplusplus
extern "C" {
#endif

/* Initialize the fixed TX net_buf pool.  Returns 0 or a negative errno. */
int hil_source_tx_init(void);

/* Attach the production stream objects (one per configured stream).
 * Called once per segment before the first send. */
int hil_source_tx_attach(struct bt_bap_stream *streams, uint8_t count);

/* Send one encoded SDU on a stream with the given sequence number.
 * Allocates from the fixed pool, copies the SDU, and hands the buffer to
 * the ISO stack.  Returns 0 on success (buffer ownership transferred) or
 * a negative errno (buffer unref'd by the driver).  Sends after
 * hil_source_tx_stop() are rejected. */
int hil_source_tx_send(uint8_t stream_idx, uint16_t seq, const uint8_t *sdu, size_t len);

/* Timestamp-pinned send (SDC timestamps mode): provide this SDU for the ISO
 * event whose CIG-event start is `ts` (controller clock, microseconds). Same
 * buffer semantics as hil_source_tx_send(). Successful submission does not
 * prove peer receipt. The coordinator only supplies future timestamps because
 * SDC flushes an SDU whose timestamp is already past when processed. */
int hil_source_tx_send_ts(uint8_t stream_idx, uint16_t seq, const uint8_t *sdu, size_t len,
			  uint32_t ts);

/* Read the controller-assigned TX timestamp (CIG event start, controller-clock
 * microseconds) for the previously provided SDU on a stream. Thread context
 * only (synchronous HCI). Returns 0 and sets *ts, or a negative errno, for
 * example -ENOTCONN before a stream has an ISO connection or during teardown. */
int hil_source_tx_read_tx_ts(uint8_t stream_idx, uint32_t *ts);

/* Read HCI LE_Read_ISO_TX_Sync for the most recently scheduled SDU. The
 * controller returns its synchronization timestamp and sequence number; this
 * does not prove peer receipt. Thread context only (synchronous HCI). */
int hil_source_tx_read_sync(uint8_t stream_idx, uint32_t *ts, uint32_t *seq);

/* Stop the TX driver: rejects further sends and clears the attached
 * stream pointers and count.  The coordinator separately clears logical
 * outstanding only after its own generation change. */
void hil_source_tx_stop(void);

#ifdef __cplusplus
}
#endif

#endif /* HIL_SOURCE_TX_H */
```
